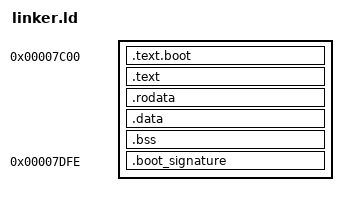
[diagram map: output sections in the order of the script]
ENTRY(_start)
SECTIONS {
    . = 0x7C00;

    .text.boot : {
        *(.text.boot)
    }

    .text : {
        *(.text)
    }

    .rodata : {
        *(.rodata)
    }

    .data : {
        *(.data)
    }

    .bss : {
        *(.bss)
        *(COMMON)
    }

    . = 0x7C00 + 510;
    .boot_signature : {
        *(.boot_signature)
    }

    /DISCARD/ : {
        *(.comment)
        *(.eh_frame)
        *(.note.gnu.property)
    }
}
